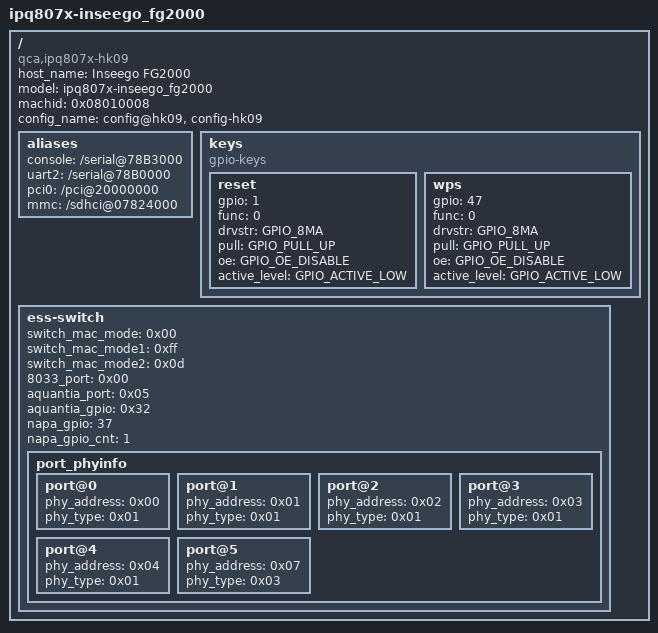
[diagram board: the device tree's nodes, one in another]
/*
 * Copyright (c) 2016 - 2018, The Linux Foundation. All rights reserved.
 *
 * This program is free software; you can redistribute it and/or modify
 * it under the terms of the GNU General Public License version 2 and
 * only version 2 as published by the Free Software Foundation.
 *
 * This program is distributed in the hope that it will be useful,
 * but WITHOUT ANY WARRANTY; without even the implied warranty of
 * MERCHANTABILITY or FITNESS FOR A PARTICULAR PURPOSE.  See the
 * GNU General Public License for more details.
 */

/dts-v1/;
#include "ipq807x-soc.dtsi"
#include <dt-bindings/qcom/gpio-ipq807x.h>
/ {
	host_name = "Inseego FG2000";
	model = "ipq807x-inseego_fg2000";
	compatible = "qca,ipq807x-hk09", "qca,ipq807x";
	machid = <0x08010008>;
	config_name = "config@hk09", "config-hk09";

	aliases {
		console = "/serial@78B3000";
		uart2 = "/serial@78B0000";
		pci0 = "/pci@20000000";
		mmc = "/sdhci@07824000";
	};

	keys {
		compatible = "gpio-keys";

        reset {
            gpio = <1>;
            func = <0>;
            drvstr = <GPIO_8MA>;
            pull = <GPIO_PULL_UP>;
            oe = <GPIO_OE_DISABLE>;
			active_level = <GPIO_ACTIVE_LOW>;
        };

        wps {
            gpio = <47>;
            func = <0>;
            drvstr = <GPIO_8MA>;
            pull = <GPIO_PULL_UP>;
            oe = <GPIO_OE_DISABLE>;
			active_level = <GPIO_ACTIVE_LOW>;
        };
    };

	ess-switch {
		switch_mac_mode = <0x00>;
		switch_mac_mode1 = <0xff>;
		switch_mac_mode2 = <0x0d>;
		8033_port = <0x00>;
		aquantia_port = <0x05>;
		aquantia_gpio = <0x32>;
		napa_gpio = <37>;
		napa_gpio_cnt = <1>;
		port_phyinfo {
			port@0 {
				phy_address = <0x00>;
				phy_type = <0x01>;
			};
			port@1 {
				phy_address = <0x01>;
				phy_type = <0x01>;
			};
			port@2 {
				phy_address = <0x02>;
				phy_type = <0x01>;
			};
			port@3 {
				phy_address = <0x03>;
				phy_type = <0x01>;
			};
			port@4 {
				phy_address = <0x04>;
				phy_type = <0x01>;
			};
			port@5 {
				phy_address = <0x07>;
				phy_type = <0x03>;
			};
		};
	};
};
